# MB9AF31xK register map
Vendor: Cypress; File version: 2.1
CPU: CM3 r2p1, little endian, MPU, no FPU, 4 interrupt priority bits
Registers are 32-bit, read-write, reset 0x0 unless marked. A register's access mark holds for its fields unless they carry their own. Offsets are from the block's base; [hi:lo] are bit positions; {n}, {i} and the like mark numbered series.

## GPIO — I/O Port Registers
Base 0x40033000
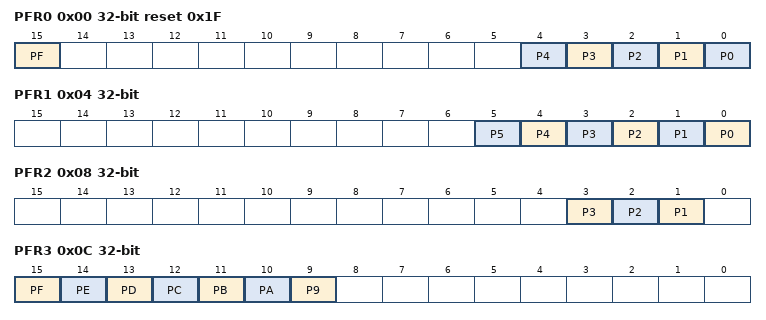
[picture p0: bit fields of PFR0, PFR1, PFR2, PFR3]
0x00 PFR0 reset 0x1F — Port Function Setting Register 0 [BHW]
  [15] PF — Bit15 of PFR0
  [n] P{n} (n=0..4) — Bit{n} of PFR0
0x04 PFR1 — Port Function Setting Register 1 [BHW]
  [n] P{n} (n=0..5) — Bit{n} of PFR1
0x08 PFR2 — Port Function Setting Register 2 [BHW]
  [3] P3 — Bit3 of PFR2
  [2] P2 — Bit2 of PFR2
  [1] P1 — Bit1 of PFR2
0x0C PFR3 — Port Function Setting Register 3 [BHW]
  [15] PF — Bit15 of PFR3
  [14] PE — Bit14 of PFR3
  [13] PD — Bit13 of PFR3
  [12] PC — Bit12 of PFR3
  [11] PB — Bit11 of PFR3
  [10] PA — Bit10 of PFR3
  [9] P9 — Bit9 of PFR3
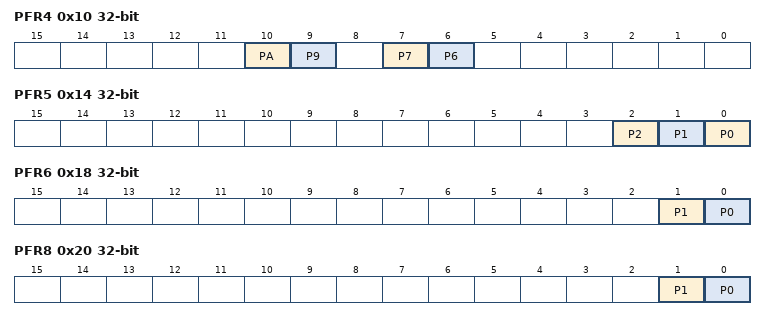
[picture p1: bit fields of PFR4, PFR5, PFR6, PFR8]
0x10 PFR4 — Port Function Setting Register 4 [BHW]
  [10] PA — Bit10 of PFR4
  [9] P9 — Bit9 of PFR4
  [7] P7 — Bit7 of PFR4
  [6] P6 — Bit6 of PFR4
0x14 PFR5 — Port Function Setting Register 5 [BHW]
  [2] P2 — Bit2 of PFR5
  [1] P1 — Bit1 of PFR5
  [0] P0 — Bit0 of PFR5
0x18 PFR6 — Port Function Setting Register 6 [BHW]
  [1] P1 — Bit1 of PFR6
  [0] P0 — Bit0 of PFR6
0x1C PFR7 reset not defined — Port Function Setting Register 7 [BHW]
0x20 PFR8 — Port Function Setting Register 8 [BHW]
  [1] P1 — Bit1 of PFR8
  [0] P0 — Bit0 of PFR8
0x24 PFR9 reset not defined — Port Function Setting Register 9 [BHW]
0x28 PFRA reset not defined — Port Function Setting Register A [BHW]
0x2C PFRB reset not defined — Port Function Setting Register B [BHW]
0x30 PFRC reset not defined — Port Function Setting Register C [BHW]
0x34 PFRD reset not defined — Port Function Setting Register D [BHW]
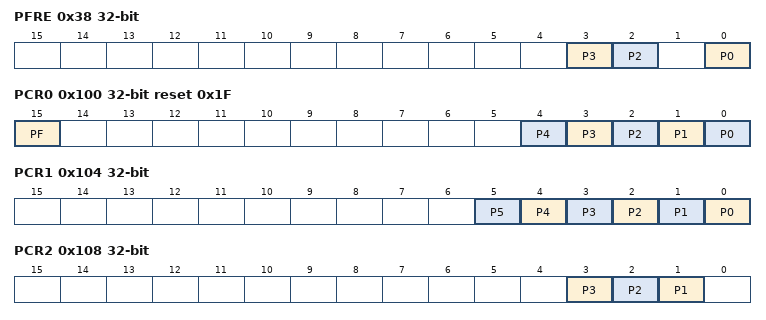
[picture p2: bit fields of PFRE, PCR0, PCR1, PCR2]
0x38 PFRE — Port Function Setting Register E [BHW]
  [3] P3 — Bit3 of PFRE
  [2] P2 — Bit2 of PFRE
  [0] P0 — Bit0 of PFRE
0x3C PFRF reset not defined — Port Function Setting Register F [BHW]
0x100 PCR0 reset 0x1F — Pull-up Setting Register 0 [BHW]
  [15] PF — Bit15 of PCR0
  [n] P{n} (n=0..4) — Bit{n} of PCR0
0x104 PCR1 — Pull-up Setting Register 1 [BHW]
  [n] P{n} (n=0..5) — Bit{n} of PCR1
0x108 PCR2 — Pull-up Setting Register 2 [BHW]
  [3] P3 — Bit3 of PCR2
  [2] P2 — Bit2 of PCR2
  [1] P1 — Bit1 of PCR2
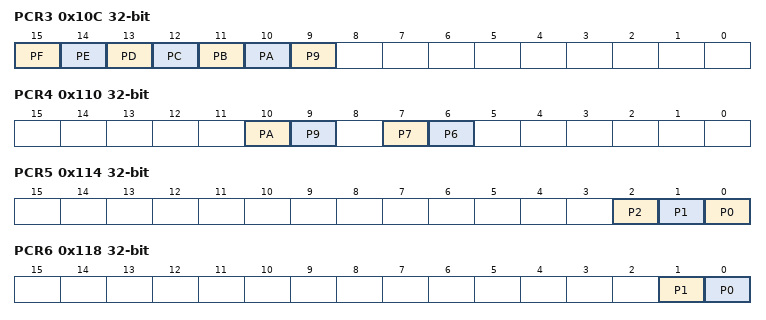
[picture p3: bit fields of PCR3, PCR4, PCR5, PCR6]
0x10C PCR3 — Pull-up Setting Register 3 [BHW]
  [15] PF — Bit15 of PCR3
  [14] PE — Bit14 of PCR3
  [13] PD — Bit13 of PCR3
  [12] PC — Bit12 of PCR3
  [11] PB — Bit11 of PCR3
  [10] PA — Bit10 of PCR3
  [9] P9 — Bit9 of PCR3
0x110 PCR4 — Pull-up Setting Register 4 [BHW]
  [10] PA — Bit10 of PCR4
  [9] P9 — Bit9 of PCR4
  [7] P7 — Bit7 of PCR4
  [6] P6 — Bit6 of PCR4
0x114 PCR5 — Pull-up Setting Register 5 [BHW]
  [2] P2 — Bit2 of PCR5
  [1] P1 — Bit1 of PCR5
  [0] P0 — Bit0 of PCR5
0x118 PCR6 — Pull-up Setting Register 6 [BHW]
  [1] P1 — Bit1 of PCR6
  [0] P0 — Bit0 of PCR6
0x11C PCR7 reset not defined — Pull-up Setting Register 7 [BHW]
0x124 PCR9 reset not defined — Pull-up Setting Register 9 [BHW]
0x128 PCRA reset not defined — Pull-up Setting Register A [BHW]
0x12C PCRB reset not defined — Pull-up Setting Register B [BHW]
0x130 PCRC reset not defined — Pull-up Setting Register C [BHW]
0x134 PCRD reset not defined — Pull-up Setting Register D [BHW]
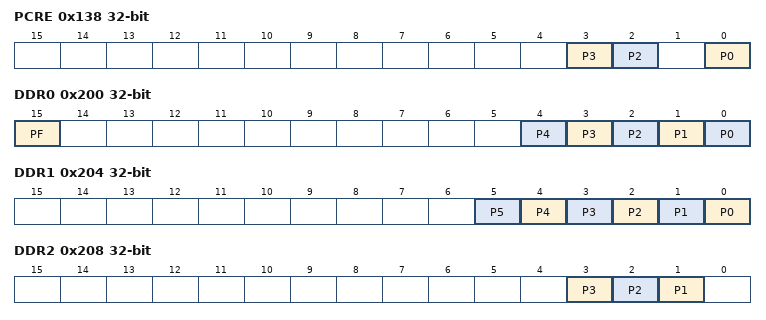
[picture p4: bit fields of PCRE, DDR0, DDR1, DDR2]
0x138 PCRE — Pull-up Setting Register E [BHW]
  [3] P3 — Bit3 of PCRE
  [2] P2 — Bit2 of PCRE
  [0] P0 — Bit0 of PCRE
0x13C PCRF reset not defined — Pull-up Setting Register F [BHW]
0x200 DDR0 — Port input/output Direction Setting Register 0 [BHW]
  [15] PF — Bit15 of DDR0
  [n] P{n} (n=0..4) — Bit{n} of DDR0
0x204 DDR1 — Port input/output Direction Setting Register 1 [BHW]
  [n] P{n} (n=0..5) — Bit{n} of DDR1
0x208 DDR2 — Port input/output Direction Setting Register 2 [BHW]
  [3] P3 — Bit3 of DDR2
  [2] P2 — Bit2 of DDR2
  [1] P1 — Bit1 of DDR2
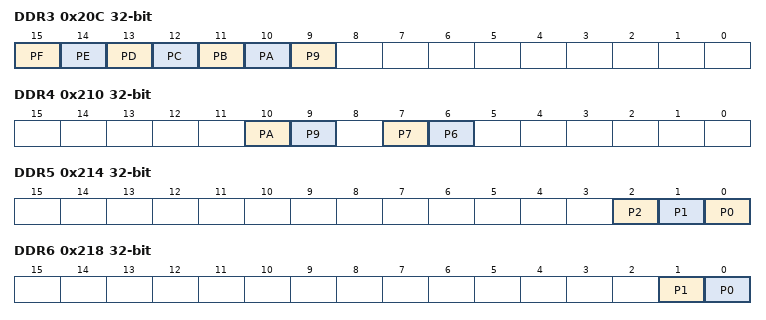
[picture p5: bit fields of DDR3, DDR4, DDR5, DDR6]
0x20C DDR3 — Port input/output Direction Setting Register 3 [BHW]
  [15] PF — Bit15 of DDR3
  [14] PE — Bit14 of DDR3
  [13] PD — Bit13 of DDR3
  [12] PC — Bit12 of DDR3
  [11] PB — Bit11 of DDR3
  [10] PA — Bit10 of DDR3
  [9] P9 — Bit9 of DDR3
0x210 DDR4 — Port input/output Direction Setting Register 4 [BHW]
  [10] PA — Bit10 of DDR4
  [9] P9 — Bit9 of DDR4
  [7] P7 — Bit7 of DDR4
  [6] P6 — Bit6 of DDR4
0x214 DDR5 — Port input/output Direction Setting Register 5 [BHW]
  [2] P2 — Bit2 of DDR5
  [1] P1 — Bit1 of DDR5
  [0] P0 — Bit0 of DDR5
0x218 DDR6 — Port input/output Direction Setting Register 6 [BHW]
  [1] P1 — Bit1 of DDR6
  [0] P0 — Bit0 of DDR6
0x21C DDR7 reset not defined — Port input/output Direction Setting Register 7 [BHW]
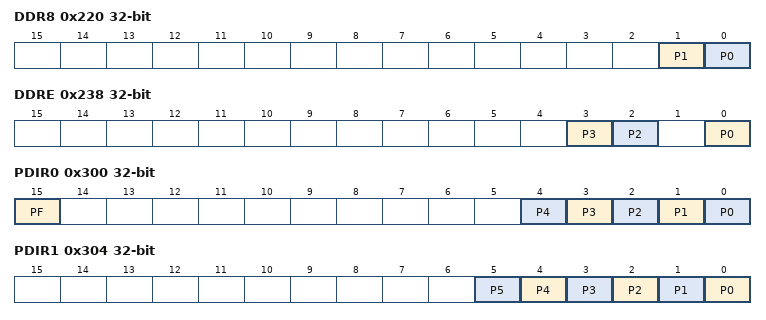
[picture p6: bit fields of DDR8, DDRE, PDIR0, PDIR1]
0x220 DDR8 — Port input/output Direction Setting Register 8 [BHW]
  [1] P1 — Bit1 of DDR8
  [0] P0 — Bit0 of DDR8
0x224 DDR9 reset not defined — Port input/output Direction Setting Register 9 [BHW]
0x228 DDRA reset not defined — Port input/output Direction Setting Register A [BHW]
0x22C DDRB reset not defined — Port input/output Direction Setting Register B [BHW]
0x230 DDRC reset not defined — Port input/output Direction Setting Register C [BHW]
0x234 DDRD reset not defined — Port input/output Direction Setting Register D [BHW]
0x238 DDRE — Port input/output Direction Setting Register E [BHW]
  [3] P3 — Bit3 of DDRE
  [2] P2 — Bit2 of DDRE
  [0] P0 — Bit0 of DDRE
0x23C DDRF reset not defined — Port input/output Direction Setting Register F [BHW]
0x300 PDIR0 ro — Port Input Data Register 0 [BHW]
  [15] PF — Bit15 of PDIR0
  [n] P{n} (n=0..4) — Bit{n} of PDIR0
0x304 PDIR1 ro — Port Input Data Register 1 [BHW]
  [n] P{n} (n=0..5) — Bit{n} of PDIR1
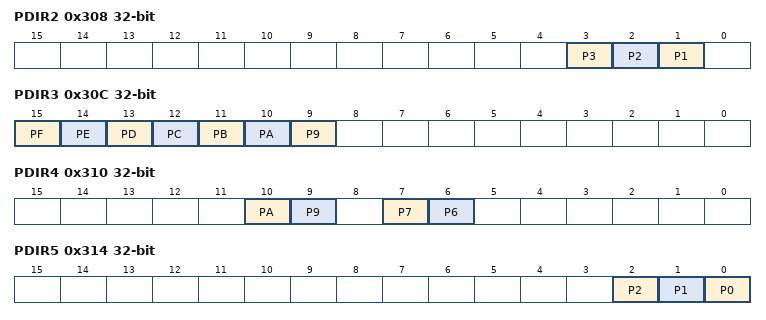
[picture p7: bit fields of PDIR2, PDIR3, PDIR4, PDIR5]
0x308 PDIR2 ro — Port Input Data Register 2 [BHW]
  [3] P3 — Bit3 of PDIR2
  [2] P2 — Bit2 of PDIR2
  [1] P1 — Bit1 of PDIR2
0x30C PDIR3 ro — Port Input Data Register 3 [BHW]
  [15] PF — Bit15 of PDIR3
  [14] PE — Bit14 of PDIR3
  [13] PD — Bit13 of PDIR3
  [12] PC — Bit12 of PDIR3
  [11] PB — Bit11 of PDIR3
  [10] PA — Bit10 of PDIR3
  [9] P9 — Bit9 of PDIR3
0x310 PDIR4 ro — Port Input Data Register 4 [BHW]
  [10] PA — Bit10 of PDIR4
  [9] P9 — Bit9 of PDIR4
  [7] P7 — Bit7 of PDIR4
  [6] P6 — Bit6 of PDIR4
0x314 PDIR5 ro — Port Input Data Register 5 [BHW]
  [2] P2 — Bit2 of PDIR5
  [1] P1 — Bit1 of PDIR5
  [0] P0 — Bit0 of PDIR5
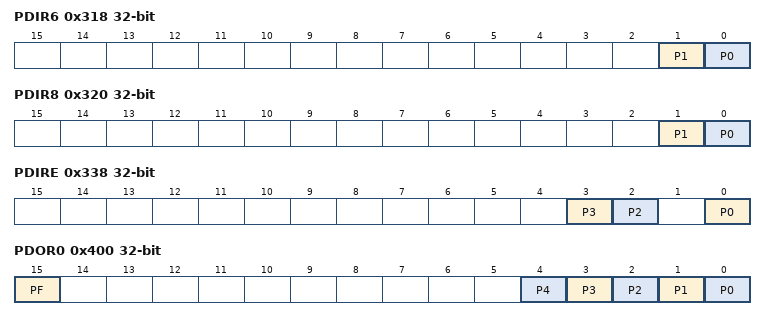
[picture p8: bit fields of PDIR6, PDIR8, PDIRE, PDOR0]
0x318 PDIR6 ro — Port Input Data Register 6 [BHW]
  [1] P1 — Bit1 of PDIR6
  [0] P0 — Bit0 of PDIR6
0x31C PDIR7 ro reset not defined — Port Input Data Register 7 [BHW]
0x320 PDIR8 ro — Port Input Data Register 8 [BHW]
  [1] P1 — Bit1 of PDIR8
  [0] P0 — Bit0 of PDIR8
0x324 PDIR9 ro reset not defined — Port Input Data Register 9 [BHW]
0x328 PDIRA ro reset not defined — Port Input Data Register A [BHW]
0x32C PDIRB ro reset not defined — Port Input Data Register B [BHW]
0x330 PDIRC ro reset not defined — Port Input Data Register C [BHW]
0x334 PDIRD ro reset not defined — Port Input Data Register D [BHW]
0x338 PDIRE ro — Port Input Data Register E [BHW]
  [3] P3 — Bit3 of PDIRE
  [2] P2 — Bit2 of PDIRE
  [0] P0 — Bit0 of PDIRE
0x33C PDIRF ro reset not defined — Port Input Data Register F [BHW]
0x400 PDOR0 — Port Output Data Register 0 [BHW]
  [15] PF — Bit15 of PDOR0
  [n] P{n} (n=0..4) — Bit{n} of PDOR0
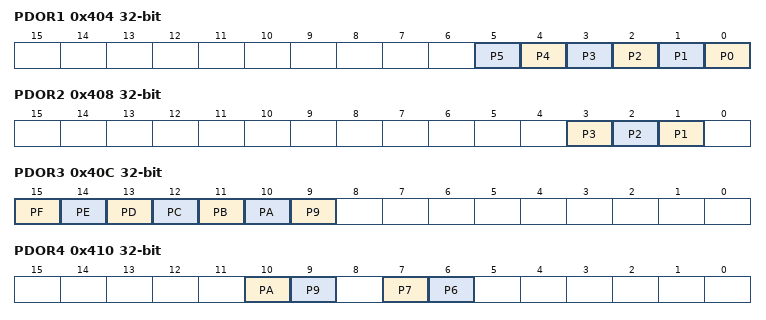
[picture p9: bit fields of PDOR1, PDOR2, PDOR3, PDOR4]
0x404 PDOR1 — Port Output Data Register 1 [BHW]
  [n] P{n} (n=0..5) — Bit{n} of PDOR1
0x408 PDOR2 — Port Output Data Register 2 [BHW]
  [3] P3 — Bit3 of PDOR2
  [2] P2 — Bit2 of PDOR2
  [1] P1 — Bit1 of PDOR2
0x40C PDOR3 — Port Output Data Register 3 [BHW]
  [15] PF — Bit15 of PDOR3
  [14] PE — Bit14 of PDOR3
  [13] PD — Bit13 of PDOR3
  [12] PC — Bit12 of PDOR3
  [11] PB — Bit11 of PDOR3
  [10] PA — Bit10 of PDOR3
  [9] P9 — Bit9 of PDOR3
0x410 PDOR4 — Port Output Data Register 4 [BHW]
  [10] PA — Bit10 of PDOR4
  [9] P9 — Bit9 of PDOR4
  [7] P7 — Bit7 of PDOR4
  [6] P6 — Bit6 of PDOR4
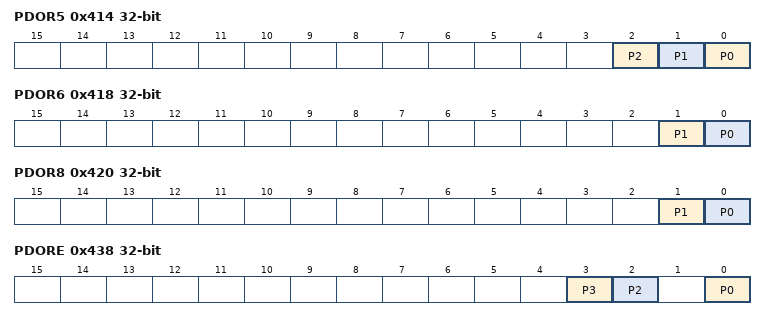
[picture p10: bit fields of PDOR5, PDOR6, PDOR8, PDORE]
0x414 PDOR5 — Port Output Data Register 5 [BHW]
  [2] P2 — Bit2 of PDOR5
  [1] P1 — Bit1 of PDOR5
  [0] P0 — Bit0 of PDOR5
0x418 PDOR6 — Port Output Data Register 6 [BHW]
  [1] P1 — Bit1 of PDOR6
  [0] P0 — Bit0 of PDOR6
0x41C PDOR7 reset not defined — Port Output Data Register 7 [BHW]
0x420 PDOR8 — Port Output Data Register 8 [BHW]
  [1] P1 — Bit1 of PDOR8
  [0] P0 — Bit0 of PDOR8
0x424 PDOR9 reset not defined — Port Output Data Register 9 [BHW]
0x428 PDORA reset not defined — Port Output Data Register A [BHW]
0x42C PDORB reset not defined — Port Output Data Register B [BHW]
0x430 PDORC reset not defined — Port Output Data Register C [BHW]
0x434 PDORD reset not defined — Port Output Data Register D [BHW]
0x438 PDORE — Port Output Data Register E [BHW]
  [3] P3 — Bit3 of PDORE
  [2] P2 — Bit2 of PDORE
  [0] P0 — Bit0 of PDORE
0x43C PDORF reset not defined — Port Output Data Register F [BHW]
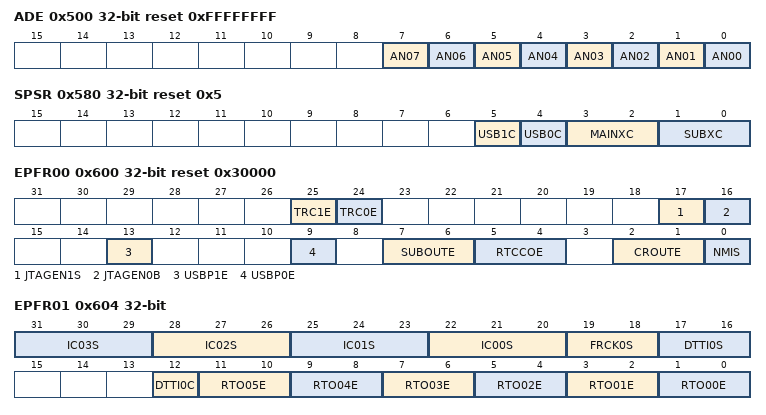
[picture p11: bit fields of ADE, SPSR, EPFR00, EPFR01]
0x500 ADE reset 0xFFFFFFFF — Analog Input Setting Register [BHW]
  [7] AN07 — Analog Input Ch.7 Setting Register
  [6] AN06 — Analog Input Ch.6 Setting Register
  [5] AN05 — Analog Input Ch.5 Setting Register
  [4] AN04 — Analog Input Ch.4 Setting Register
  [3] AN03 — Analog Input Ch.3 Setting Register
  [2] AN02 — Analog Input Ch.2 Setting Register
  [1] AN01 — Analog Input Ch.1 Setting Register
  [0] AN00 — Analog Input Ch.0 Setting Register
0x580 SPSR reset 0x5 — Special Port Setting Register [BHW]
  [5] USB1C — USB (ch.1) Pin Setting Register
  [4] USB0C — USB (ch.0) Pin Setting Register
  [3:2] MAINXC — Main Clock (Oscillation) Pin Setting Register
  [1:0] SUBXC — Sub Clock (Oscillation) Pin Setting Register
0x600 EPFR00 reset 0x30000 — Extended Pin Function Setting Register 00 [BHW]
  [25] TRC1E — TRACED Function Select bit 1
  [24] TRC0E — TRACED Function Select bit 0
  [17] JTAGEN1S — JTAG Function Select bit 1
  [16] JTAGEN0B — JTAG Function Select bit 0
  [13] USBP1E — USB ch.1 Function Select bit 1
  [9] USBP0E — USB ch.0 Function Select bit 1
  [7:6] SUBOUTE — Sub clock divide output function select bit
  [5:4] RTCCOE — RTC clock output select bit
  [2:1] CROUTE — Internal high-speed CR Oscillation Output Function Select bit
  [0] NMIS — NMIX Function Select bit
0x604 EPFR01 — Extended Pin Function Setting Register 01 [BHW]
  [3n+22:3n+20] IC{n:02}S (n=0..3) — IC{n:02} Input Select bits
  [19:18] FRCK0S — FRCK0 Input Select bits
  [17:16] DTTI0S — DTTIX0 Input Select bits
  [12] DTTI0C — DTTIX0 Function Select bit
  [2n+1:2n] RTO{n:02}E (n=0..5) — RTO{n:02} Output Select bits
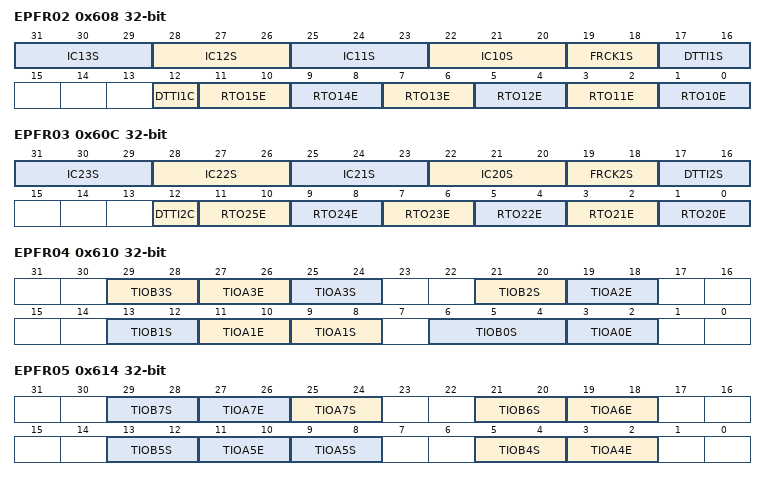
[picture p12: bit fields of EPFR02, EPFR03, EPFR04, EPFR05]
0x608 EPFR02 — Extended Pin Function Setting Register 02 [BHW]
  [3n-8:3n-10] IC{n}S (n=10..13) — IC{n} Input Select bits
  [19:18] FRCK1S — FRCK1 Input Select bits
  [17:16] DTTI1S — DTTIX1 Input Select bits
  [12] DTTI1C — DTTIX1 Function Select bit
  [2n-19:2n-20] RTO{n}E (n=10..15) — RTO{n} Output Select bits
0x60C EPFR03 — Extended Pin Function Setting Register 03 [BHW]
  [3n-38:3n-40] IC{n}S (n=20..23) — IC{n} Input Select bits
  [19:18] FRCK2S — FRCK2 Input Select bits
  [17:16] DTTI2S — DTTIX2 Input Select bits
  [12] DTTI2C — DTTIX2 Function Select bit
  [2n-39:2n-40] RTO{n}E (n=20..25) — RTO{n} Output Select bits
0x610 EPFR04 — Extended Pin Function Setting Register 04 [BHW]
  [29:28] TIOB3S — TIOB3 Input Select bits
  [8n+3:8n+2] TIOA{n}E (n=0..3) — TIOA{n} Output Select bits
  [25:24] TIOA3S — TIOA3 Input Select bits
  [21:20] TIOB2S — TIOB2 Input Select bits
  [13:12] TIOB1S — TIOB1 Input Select bits
  [9:8] TIOA1S — TIOA1 Input Select bits
  [6:4] TIOB0S — TIOB0 Input Select bits
0x614 EPFR05 — Extended Pin Function Setting Register 05 [BHW]
  [8n-27:8n-28] TIOB{n}S (n=4..7) — TIOB{n} Input Select bits
  [8n-29:8n-30] TIOA{n}E (n=4..7) — TIOA{n} Output Select bits
  [25:24] TIOA7S — TIOA7 Input Select bits
  [9:8] TIOA5S — TIOA5 Input Select bits
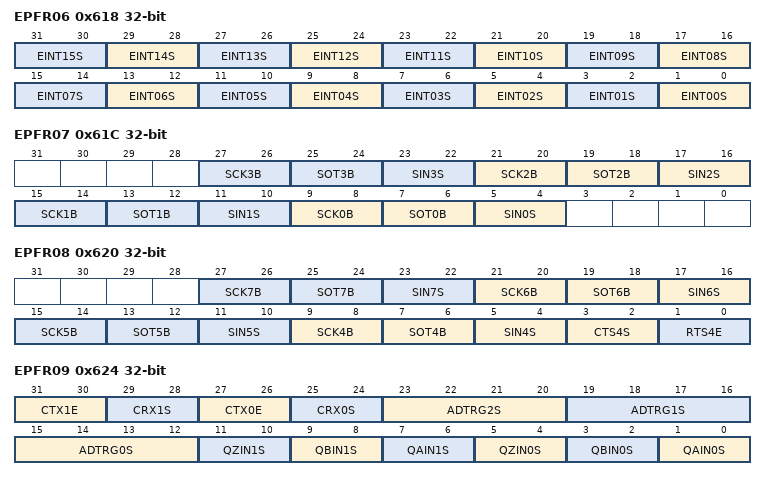
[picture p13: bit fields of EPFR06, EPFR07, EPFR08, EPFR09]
0x618 EPFR06 — Extended Pin Function Setting Register 06 [BHW]
  [2n+1:2n] EINT{n:02}S (n=0..15) — External Interrupt {n:02} Input Select bits
0x61C EPFR07 — Extended Pin Function Setting Register 07 [BHW]
  [6n+9:6n+8] SCK{n}B (n=0..3) — SCK{n} Input/Output Select bits
  [6n+7:6n+6] SOT{n}B (n=0..3) — SOT{n} Input/Output Select bits
  [6n+5:6n+4] SIN{n}S (n=0..3) — SIN{n} Input Select bits
0x620 EPFR08 — Extended Pin Function Setting Register 08 [BHW]
  [6n-15:6n-16] SCK{n}B (n=4..7) — SCK{n} Input/Output Select bits
  [6n-17:6n-18] SOT{n}B (n=4..7) — SOT{n} Input/Output Select bits
  [6n-19:6n-20] SIN{n}S (n=4..7) — SIN{n} Input Select bits
  [3:2] CTS4S — CTS4 Input Select bits
  [1:0] RTS4E — RTS4 Output Select bits
0x624 EPFR09 — Extended Pin Function Setting Register 09 [BHW]
  [31:30] CTX1E — CTX1E Output Select bits
  [29:28] CRX1S — CRX1S Input Select bits
  [27:26] CTX0E — CTX0E Output Select bits
  [25:24] CRX0S — CRX0S Input Select bits
  [23:20] ADTRG2S — ADTRG2 Input Select bits
  [19:16] ADTRG1S — ADTRG1 Input Select bits
  [15:12] ADTRG0S — ADTRG0 Input Select bits
  [11:10] QZIN1S — QZIN1S Input Select bits
  [9:8] QBIN1S — QBIN1S Input Select bits
  [7:6] QAIN1S — QAIN1S Input Select bits
  [5:4] QZIN0S — QZIN0S Input Select bits
  [3:2] QBIN0S — QBIN0S Input Select bits
  [1:0] QAIN0S — QAIN0S Input Select bits
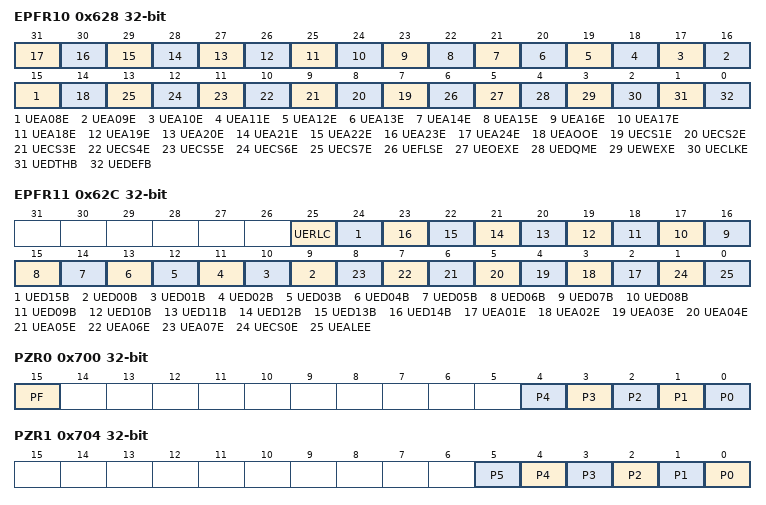
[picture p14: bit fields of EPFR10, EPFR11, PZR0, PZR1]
0x628 EPFR10 — Extended pin function setting register 10 [BHW]
  [n+7] UEA{n:02}E (n=8..24) — UEA{n:02}E output select bit
  [14] UEAOOE — UEAOOE output select bit
  [n+6] UECS{n}E (n=1..7) — UECS{n}E output select bit
  [6] UEFLSE — UEFLSE output select bit
  [5] UEOEXE — UEOEXE output select bit
  [4] UEDQME — UEDQME output select bit
  [3] UEWEXE — UEWEXE output select bit
  [2] UECLKE — UECLKE output select bit
  [1] UEDTHB — UEDTHB input/output select bit
  [0] UEDEFB — UEDEFB input/output select bit
0x62C EPFR11 — Extended pin function setting register 11 [BHW]
  [25] UERLC — UERLC relocation select bit
  [24] UED15B — UED15B input/output select bit
  [n+9] UED{n:02}B (n=0..14) — UED{n:02}B output select bit
  [n+1] UEA{n:02}E (n=1..7) — UEA{n:02}E output select bit
  [1] UECS0E — UECS0E output select bit
  [0] UEALEE — UEALEE output select bit
0x700 PZR0 — Port Pseudo Open Drain Setting Register 0 [BHW]
  [15] PF — Bit15 of PZR0
  [n] P{n} (n=0..4) — Bit{n} of PZR0
0x704 PZR1 — Port Pseudo Open Drain Setting Register 1 [BHW]
  [n] P{n} (n=0..5) — Bit{n} of PZR1
0x708 PZR2 — Port Pseudo Open Drain Setting Register 2 [BHW]
  [3] P3 — Bit3 of PZR2
  [2] P2 — Bit2 of PZR2
  [1] P1 — Bit1 of PZR2
0x70C PZR3 — Port Pseudo Open Drain Setting Register 3 [BHW]
  [15] PF — Bit15 of PZR3
  [14] PE — Bit14 of PZR3
  [13] PD — Bit13 of PZR3
  [12] PC — Bit12 of PZR3
  [11] PB — Bit11 of PZR3
  [10] PA — Bit10 of PZR3
  [9] P9 — Bit9 of PZR3
0x710 PZR4 — Port Pseudo Open Drain Setting Register 4 [BHW]
  [10] PA — Bit10 of PZR4
  [9] P9 — Bit9 of PZR4
  [7] P7 — Bit7 of PZR4
  [6] P6 — Bit6 of PZR4
0x714 PZR5 — Port Pseudo Open Drain Setting Register 5 [BHW]
  [2] P2 — Bit2 of PZR5
  [1] P1 — Bit1 of PZR5
  [0] P0 — Bit0 of PZR5
0x718 PZR6 — Port Pseudo Open Drain Setting Register 6 [BHW]
  [1] P1 — Bit1 of PZR6
  [0] P0 — Bit0 of PZR6
0x71C PZR7 reset not defined — Port Pseudo Open Drain Setting Register 7 [BHW]
0x720 PZR8 — Port Pseudo Open Drain Setting Register 8 [BHW]
  [1] P1 — Bit1 of PZR8
  [0] P0 — Bit0 of PZR8
0x724 PZR9 reset not defined — Port Pseudo Open Drain Setting Register 9 [BHW]
0x728 PZRA reset not defined — Port Pseudo Open Drain Setting Register A [BHW]
0x72C PZRB reset not defined — Port Pseudo Open Drain Setting Register B [BHW]
0x730 PZRC reset not defined — Port Pseudo Open Drain Setting Register C [BHW]
0x734 PZRD reset not defined — Port Pseudo Open Drain Setting Register D [BHW]
0x738 PZRE — Port Pseudo Open Drain Setting Register E [BHW]
  [3] P3 — Bit3 of PZRE
  [2] P2 — Bit2 of PZRE
  [0] P0 — Bit0 of PZRE
0x73C PZRF reset not defined — Port Pseudo Open Drain Setting Register F [BHW]
